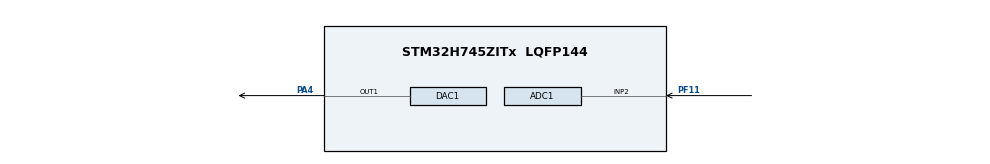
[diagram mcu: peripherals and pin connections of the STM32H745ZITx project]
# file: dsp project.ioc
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ADC1.Channel-0\#ChannelRegularConversion=ADC_CHANNEL_2
ADC1.ContinuousConvMode=ENABLE
ADC1.EOCSelection=ADC_EOC_SEQ_CONV
ADC1.NbrOfConversionFlag=1
ADC1.OffsetNumber-0\#ChannelRegularConversion=ADC_OFFSET_NONE
ADC1.OffsetSignedSaturation-0\#ChannelRegularConversion=DISABLE
ADC1.Overrun=ADC_OVR_DATA_OVERWRITTEN
ADC1.Rank-0\#ChannelRegularConversion=1
ADC1.Resolution=ADC_RESOLUTION_12B
ADC1.SamplingTime-0\#ChannelRegularConversion=ADC_SAMPLETIME_64CYCLES_5
ADC1.master=1
CortexM4.IPs=FATFS_M4\:I,FREERTOS_M4\:I,IWDG2\:I,RCC,WWDG2\:I,DMA,BDMA,MDMA,NVIC2\:I,USART3,ETH,DEBUG,USB_DEVICE_M4\:I,USB_HOST_M4\:I,PDM2PCM_M4\:I,PWR,RESMGR_UTILITY,SYS_M4\:I,CORTEX_M4\:I,OPENAMP_M4\:I,VREFBUF,GPIO
CortexM7.IPs=FATFS_M7\:I,FREERTOS_M7\:I,IWDG1\:I,RCC\:I,WWDG1\:I,DMA\:I,BDMA\:I,MDMA\:I,NVIC1\:I,SYS\:I,USART3\:I,USB_OTG_FS\:I,ETH\:I,CORTEX_M7\:I,DEBUG\:I,USB_DEVICE_M7\:I,USB_HOST_M7\:I,PDM2PCM_M7\:I,PWR\:I,RESMGR_UTILITY\:I,OPENAMP_M7\:I,VREFBUF\:I,GPIO\:I,DAC1\:I,TIM1\:I,ADC1\:I
DAC1.DAC_Channel-DAC_OUT1=DAC_CHANNEL_1
DAC1.DAC_Trigger-DAC_OUT1=DAC_TRIGGER_T1_TRGO
Dma.DAC1_CH1.0.Direction=DMA_MEMORY_TO_PERIPH
Dma.DAC1_CH1.0.EventEnable=DISABLE
Dma.DAC1_CH1.0.FIFOMode=DMA_FIFOMODE_DISABLE
Dma.DAC1_CH1.0.Instance=DMA1_Stream0
Dma.DAC1_CH1.0.MemDataAlignment=DMA_MDATAALIGN_HALFWORD
Dma.DAC1_CH1.0.MemInc=DMA_MINC_ENABLE
Dma.DAC1_CH1.0.Mode=DMA_CIRCULAR
Dma.DAC1_CH1.0.PeriphDataAlignment=DMA_PDATAALIGN_HALFWORD
Dma.DAC1_CH1.0.PeriphInc=DMA_PINC_DISABLE
Dma.DAC1_CH1.0.Polarity=HAL_DMAMUX_REQ_GEN_RISING
Dma.DAC1_CH1.0.Priority=DMA_PRIORITY_LOW
Dma.DAC1_CH1.0.RequestNumber=1
Dma.DAC1_CH1.0.SignalID=NONE
Dma.DAC1_CH1.0.SyncEnable=DISABLE
Dma.DAC1_CH1.0.SyncPolarity=HAL_DMAMUX_SYNC_NO_EVENT
Dma.DAC1_CH1.0.SyncRequestNumber=1
Dma.DAC1_CH1.0.SyncSignalID=NONE
Dma.Request0=DAC1_CH1
Mcu.Family=STM32H7
Mcu.Name=STM32H745ZITx
Mcu.Package=LQFP144
NVIC1.DMA1_Stream0_IRQn=true\:0\:0\:false\:false\:true\:false\:true\:true
NVIC1.PriorityGroup=NVIC_PRIORITYGROUP_4
NVIC1.TIM1_UP_IRQn=true\:0\:0\:false\:false\:true\:true\:true\:true
NVIC2.PriorityGroup=NVIC_PRIORITYGROUP_4
PA4.PinAttribute=CortexM7
PA4.Signal=COMP_DAC11_group
PF11.Mode=IN2-Single-Ended
PF11.PinAttribute=CortexM7
PF11.Signal=ADC1_INP2
ProjectManager.HeapSize=M4-0x200,M7-0x200
ProjectManager.StackSize=M4-0x400,M7-0x400
ProjectManager.TargetToolchain=STM32CubeIDE
RCC.ADCFreq_Value=37500000
RCC.APB1Freq_Value=4000000
RCC.APB2Freq_Value=4000000
RCC.APB3Freq_Value=8000000
RCC.APB4Freq_Value=8000000
RCC.CortexFreq_Value=16000000
RCC.D1PPRE=RCC_APB3_DIV2
RCC.D2PPRE1=RCC_APB1_DIV4
RCC.D2PPRE2=RCC_APB2_DIV4
RCC.D3PPRE=RCC_APB4_DIV2
RCC.DIVM1=4
RCC.DIVM2=4
RCC.DIVM3=1
RCC.DIVN1=10
RCC.DIVN2=9
RCC.DIVN3=18
RCC.DIVP1=10
RCC.DIVP2=4
RCC.DIVQ3=3
RCC.HCLKFreq_Value=16000000
RCC.HSE_VALUE=8000000
RCC.PLL2FRACN=3072
RCC.PLLFRACN=0
RCC.SYSCLKFreq_VALUE=16000000
RCC.SYSCLKSource=RCC_SYSCLKSOURCE_PLLCLK
RCC.SupplySource=PWR_DIRECT_SMPS_SUPPLY
RCC.USBCLockSelection=RCC_USBCLKSOURCE_PLL3
RCC.USBFreq_Value=384000000
SH.COMP_DAC11_group.0=DAC1_OUT1,DAC_OUT1
TIM1.Period=1000-1
TIM1.Prescaler=16-1
TIM1.TIM_MasterOutputTrigger=TIM_TRGO_UPDATE
TIM1.TIM_MasterOutputTrigger2=TIM_TRGO2_RESET
VP_SYS_M4_VS_Systick.Mode=SysTick
VP_TIM1_VS_ClockSourceINT.Mode=Internal
board=NUCLEO-H745ZI-Q

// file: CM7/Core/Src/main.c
/* USER CODE BEGIN Header */
/**
 ******************************************************************************
 * @file           : main.c
 * @brief          : Main program body
 ******************************************************************************
 * @attention
 *
 * Copyright (c) 2023 STMicroelectronics.
 * All rights reserved.
 *
 * This software is licensed under terms that can be found in the LICENSE file
 * in the root directory of this software component.
 * If no LICENSE file comes with this software, it is provided AS-IS.
 *
 ******************************************************************************
 */
/* USER CODE END Header */
#include "main.h"

/* USER CODE BEGIN PD */

#ifndef HSEM_ID_0
#define HSEM_ID_0 (0U) /* HW semaphore 0*/
#endif
/* USER CODE END PD */

ADC_HandleTypeDef hadc1;

DAC_HandleTypeDef hdac1;
DMA_HandleTypeDef hdma_dac1_ch1;

TIM_HandleTypeDef htim1;

/* USER CODE BEGIN PV */
uint16_t Data[1000];
/* USER CODE END PV */

void SystemClock_Config(void);
static void MX_GPIO_Init(void);
static void MX_DMA_Init(void);
static void MX_DAC1_Init(void);
static void MX_TIM1_Init(void);
static void MX_ADC1_Init(void);
/* USER CODE BEGIN PFP */
void generate_points(void);
/* USER CODE END PFP */

/* USER CODE BEGIN 0 */
uint16_t adc_value = 0;
/* USER CODE END 0 */

int main(void)
{
  /* USER CODE BEGIN 1 */
	generate_points();
  /* USER CODE END 1 */

  /* MCU Configuration--------------------------------------------------------*/

  /* Reset of all peripherals, Initializes the Flash interface and the Systick. */
  HAL_Init();

  /* Configure the system clock */
  SystemClock_Config();

  /* Initialize all configured peripherals */
  MX_GPIO_Init();
  MX_DMA_Init();
  MX_DAC1_Init();
  MX_TIM1_Init();
  MX_ADC1_Init();
  /* USER CODE BEGIN 2 */

  HAL_TIM_Base_Start(&htim1);
	HAL_DAC_Start_DMA(&hdac1, DAC_CHANNEL_1,(uint32_t*) Data, 1000, DAC_ALIGN_12B_R);
	HAL_ADC_Start(&hadc1);
  /* USER CODE END 2 */

  /* Infinite loop */
	while (1)
	{

    /* USER CODE BEGIN 3 */
		adc_value = HAL_ADC_GetValue(&hadc1);
  }
  /* USER CODE END 3 */
}

void SystemClock_Config(void)
{
  RCC_OscInitTypeDef RCC_OscInitStruct = {0};
  RCC_ClkInitTypeDef RCC_ClkInitStruct = {0};

  /** Supply configuration update enable
  */
  HAL_PWREx_ConfigSupply(PWR_DIRECT_SMPS_SUPPLY);

  /** Configure the main internal regulator output voltage
  */
  __HAL_PWR_VOLTAGESCALING_CONFIG(PWR_REGULATOR_VOLTAGE_SCALE3);

  while(!__HAL_PWR_GET_FLAG(PWR_FLAG_VOSRDY)) {}

  /** Macro to configure the PLL clock source
  */
  __HAL_RCC_PLL_PLLSOURCE_CONFIG(RCC_PLLSOURCE_HSI);

  /** Initializes the RCC Oscillators according to the specified parameters
  * in the RCC_OscInitTypeDef structure.
  */
  RCC_OscInitStruct.OscillatorType = RCC_OSCILLATORTYPE_HSI;
  RCC_OscInitStruct.HSIState = RCC_HSI_DIV1;
  RCC_OscInitStruct.HSICalibrationValue = RCC_HSICALIBRATION_DEFAULT;
  RCC_OscInitStruct.PLL.PLLState = RCC_PLL_ON;
  RCC_OscInitStruct.PLL.PLLSource = RCC_PLLSOURCE_HSI;
  RCC_OscInitStruct.PLL.PLLM = 4;
  RCC_OscInitStruct.PLL.PLLN = 10;
  RCC_OscInitStruct.PLL.PLLP = 10;
  RCC_OscInitStruct.PLL.PLLQ = 2;
  RCC_OscInitStruct.PLL.PLLR = 2;
  RCC_OscInitStruct.PLL.PLLRGE = RCC_PLL1VCIRANGE_3;
  RCC_OscInitStruct.PLL.PLLVCOSEL = RCC_PLL1VCOMEDIUM;
  RCC_OscInitStruct.PLL.PLLFRACN = 0;
  if (HAL_RCC_OscConfig(&RCC_OscInitStruct) != HAL_OK)
  {
    Error_Handler();
  }

  /** Initializes the CPU, AHB and APB buses clocks
  */
  RCC_ClkInitStruct.ClockType = RCC_CLOCKTYPE_HCLK|RCC_CLOCKTYPE_SYSCLK
                              |RCC_CLOCKTYPE_PCLK1|RCC_CLOCKTYPE_PCLK2
                              |RCC_CLOCKTYPE_D3PCLK1|RCC_CLOCKTYPE_D1PCLK1;
  RCC_ClkInitStruct.SYSCLKSource = RCC_SYSCLKSOURCE_PLLCLK;
  RCC_ClkInitStruct.SYSCLKDivider = RCC_SYSCLK_DIV1;
  RCC_ClkInitStruct.AHBCLKDivider = RCC_HCLK_DIV1;
  RCC_ClkInitStruct.APB3CLKDivider = RCC_APB3_DIV2;
  RCC_ClkInitStruct.APB1CLKDivider = RCC_APB1_DIV4;
  RCC_ClkInitStruct.APB2CLKDivider = RCC_APB2_DIV4;
  RCC_ClkInitStruct.APB4CLKDivider = RCC_APB4_DIV2;

  if (HAL_RCC_ClockConfig(&RCC_ClkInitStruct, FLASH_LATENCY_0) != HAL_OK)
  {
    Error_Handler();
  }
}

static void MX_ADC1_Init(void)
{

  ADC_MultiModeTypeDef multimode = {0};
  ADC_ChannelConfTypeDef sConfig = {0};

  /** Common config
  */
  hadc1.Instance = ADC1;
  hadc1.Init.ClockPrescaler = ADC_CLOCK_ASYNC_DIV1;
  hadc1.Init.Resolution = ADC_RESOLUTION_12B;
  hadc1.Init.ScanConvMode = ADC_SCAN_DISABLE;
  hadc1.Init.EOCSelection = ADC_EOC_SEQ_CONV;
  hadc1.Init.LowPowerAutoWait = DISABLE;
  hadc1.Init.ContinuousConvMode = ENABLE;
  hadc1.Init.NbrOfConversion = 1;
  hadc1.Init.DiscontinuousConvMode = DISABLE;
  hadc1.Init.ExternalTrigConv = ADC_SOFTWARE_START;
  hadc1.Init.ExternalTrigConvEdge = ADC_EXTERNALTRIGCONVEDGE_NONE;
  hadc1.Init.ConversionDataManagement = ADC_CONVERSIONDATA_DR;
  hadc1.Init.Overrun = ADC_OVR_DATA_OVERWRITTEN;
  hadc1.Init.LeftBitShift = ADC_LEFTBITSHIFT_NONE;
  hadc1.Init.OversamplingMode = DISABLE;
  if (HAL_ADC_Init(&hadc1) != HAL_OK)
  {
    Error_Handler();
  }

  /** Configure the ADC multi-mode
  */
  multimode.Mode = ADC_MODE_INDEPENDENT;
  if (HAL_ADCEx_MultiModeConfigChannel(&hadc1, &multimode) != HAL_OK)
  {
    Error_Handler();
  }

  /** Configure Regular Channel
  */
  sConfig.Channel = ADC_CHANNEL_2;
  sConfig.Rank = ADC_REGULAR_RANK_1;
  sConfig.SamplingTime = ADC_SAMPLETIME_64CYCLES_5;
  sConfig.SingleDiff = ADC_SINGLE_ENDED;
  sConfig.OffsetNumber = ADC_OFFSET_NONE;
  sConfig.Offset = 0;
  sConfig.OffsetSignedSaturation = DISABLE;
  if (HAL_ADC_ConfigChannel(&hadc1, &sConfig) != HAL_OK)
  {
    Error_Handler();
  }

}

static void MX_DAC1_Init(void)
{

  DAC_ChannelConfTypeDef sConfig = {0};

  /** DAC Initialization
  */
  hdac1.Instance = DAC1;
  if (HAL_DAC_Init(&hdac1) != HAL_OK)
  {
    Error_Handler();
  }

  /** DAC channel OUT1 config
  */
  sConfig.DAC_SampleAndHold = DAC_SAMPLEANDHOLD_DISABLE;
  sConfig.DAC_Trigger = DAC_TRIGGER_T1_TRGO;
  sConfig.DAC_OutputBuffer = DAC_OUTPUTBUFFER_ENABLE;
  sConfig.DAC_ConnectOnChipPeripheral = DAC_CHIPCONNECT_DISABLE;
  sConfig.DAC_UserTrimming = DAC_TRIMMING_FACTORY;
  if (HAL_DAC_ConfigChannel(&hdac1, &sConfig, DAC_CHANNEL_1) != HAL_OK)
  {
    Error_Handler();
  }

}

static void MX_TIM1_Init(void)
{

  TIM_ClockConfigTypeDef sClockSourceConfig = {0};
  TIM_MasterConfigTypeDef sMasterConfig = {0};

  htim1.Instance = TIM1;
  htim1.Init.Prescaler = 0;
  htim1.Init.CounterMode = TIM_COUNTERMODE_UP;
  htim1.Init.Period =799;
  htim1.Init.ClockDivision = TIM_CLOCKDIVISION_DIV1;
  htim1.Init.RepetitionCounter = 0;
  htim1.Init.AutoReloadPreload = TIM_AUTORELOAD_PRELOAD_DISABLE;
  if (HAL_TIM_Base_Init(&htim1) != HAL_OK)
  {
    Error_Handler();
  }
  sClockSourceConfig.ClockSource = TIM_CLOCKSOURCE_INTERNAL;
  if (HAL_TIM_ConfigClockSource(&htim1, &sClockSourceConfig) != HAL_OK)
  {
    Error_Handler();
  }
  sMasterConfig.MasterOutputTrigger = TIM_TRGO_UPDATE;
  sMasterConfig.MasterOutputTrigger2 = TIM_TRGO2_RESET;
  sMasterConfig.MasterSlaveMode = TIM_MASTERSLAVEMODE_DISABLE;
  if (HAL_TIMEx_MasterConfigSynchronization(&htim1, &sMasterConfig) != HAL_OK)
  {
    Error_Handler();
  }

}

static void MX_DMA_Init(void)
{

  /* DMA controller clock enable */
  __HAL_RCC_DMA1_CLK_ENABLE();

  /* DMA interrupt init */
  /* DMA1_Stream0_IRQn interrupt configuration */
  HAL_NVIC_SetPriority(DMA1_Stream0_IRQn, 0, 0);
  HAL_NVIC_EnableIRQ(DMA1_Stream0_IRQn);

}

static void MX_GPIO_Init(void)
{

  /* GPIO Ports Clock Enable */
  __HAL_RCC_GPIOA_CLK_ENABLE();
  __HAL_RCC_GPIOF_CLK_ENABLE();

}

/* USER CODE BEGIN 4 */
void generate_points(void)
{
	for ( int i=0 ; i<1000; i++)
	{
		Data[i] = (uint16_t) ((sin(2*M_PI * i *0.001 ) + 1) *4095.0 / 2.0 );
	}

}
/* USER CODE END 4 */

void Error_Handler(void)
{
	__disable_irq();
	while (1)
	{
	}
}
